# S32R372 register map
Vendor: Freescale Semiconductor, Inc.; Series: Qorivva; File version: 1.6
Registers are 32-bit, read-write, reset 0x0 unless marked. A register's access mark holds for its fields unless they carry their own. Offsets are from the block's base; [hi:lo] are bit positions; 'fields as' and 'values as' point back to an identical list.

## RGM — Unless otherwise noted, all registers may be accessed as 32-bit words, 16-bit half-words, or 8-bit bytes.
Base 0xFFFA8000; register names take the prefix RGM_
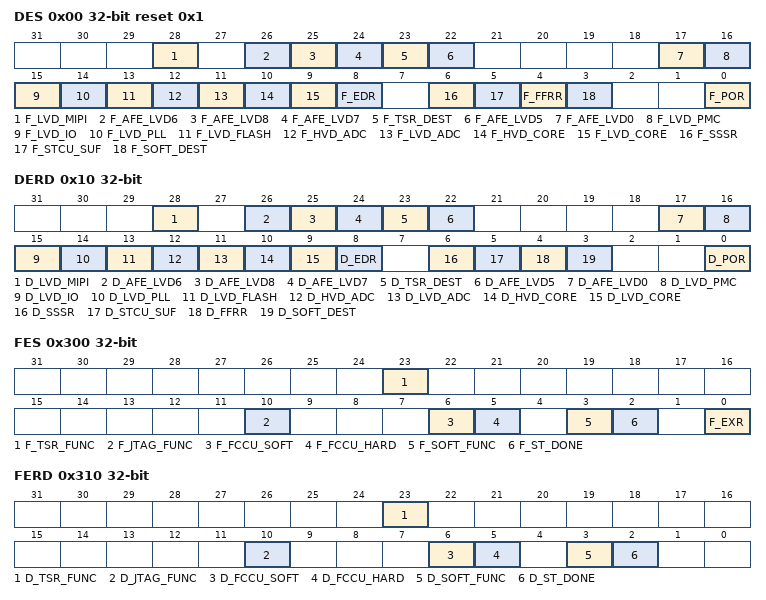
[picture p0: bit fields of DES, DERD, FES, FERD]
0x00 DES reset 0x1 — 'Destructive' Event Status Register
  [28] F_LVD_MIPI — LVD on MIPI voltage
    0=No MIPI LVD voltage 'destructive' reset event has occurred since the last clear; 1=A MIPI LVD voltage 'destructive' reset event has occurred
  [26] F_AFE_LVD6 — AFE LVD 'destructive' reset event has occurred due toAFE SDPLL analog circuitry
    0=No AFE LVD 'destructive' reset event has occurred since the last clear; 1=An AFE LVD 'destructive' reset event has occurred
  [25] F_AFE_LVD8 — AFE LVD 'destructive' reset event has occurred due to level shifter logic
    values as F_AFE_LVD6
  [24] F_AFE_LVD7 — AFE LVD 'destructive' reset event has occurred due to AFE SDPLL digital circuitry
    values as F_AFE_LVD6
  [23] F_TSR_DEST — Flag for temperature sensor 'destructive' reset
    0=No temperature sensor 'destructive' reset event has occurred since the last clear; 1=A temperature sensor 'destructive' reset event has occurred
  [22] F_AFE_LVD5 — AFE LVD 'destructive' reset event has occurred due to AFE OSC circuitry
    values as F_AFE_LVD6
  [17] F_AFE_LVD0 — AFE LVD 'destructive' reset event has occurred due to VDD_HV_RAW.
    values as F_AFE_LVD6
  [16] F_LVD_PMC — LVD on PMC voltage A destructive reset on the PMC voltage supply LVD (LVD_PMC) will also set the external reset status in RGM_FES[F_EXR]
    0=No PMC LVD voltage 'destructive' reset event has occurred since the last clear; 1=A PMC LVD voltage 'destructive' reset event has occurred
  [15] F_LVD_IO — LVD on I/O voltage
    0=No I/O LVD voltage 'destructive' reset event has occurred since the last clear; 1=An I/O LVD voltage 'destructive' reset event has occurred
  [14] F_LVD_PLL — LVD on PLL voltage
    0=No PLL LVD voltage 'destructive' reset event has occurred since the last clear; 1=A PLL LVD voltage 'destructive' reset event has occurred
  [13] F_LVD_FLASH — LVD on Flash voltage
    0=No Flash LVD voltage 'destructive' reset event has occurred since the last clear; 1=A Flash LVD voltage 'destructive' event has occurred
  [12] F_HVD_ADC — HVD on ADC voltage
    0=No ADC HVD voltage 'destructive' reset event has occurred since the last clear; 1=An ADC HVD voltage 'destructive' reset event has occurred
  [11] F_LVD_ADC — LVD on ADC voltage
    0=No ADC LVD voltage 'destructive' reset event has occurred since the last clear; 1=An ADC LVD voltage 'destructive' reset event has occurred
  [10] F_HVD_CORE — HVD on core voltage
    0=No core HVD voltage 'destructive' reset event has occurred since the last clear; 1=A core HVD voltage 'destructive' reset event has occurred
  [9] F_LVD_CORE — LVD on core voltage
    0=No core LVD voltage 'destructive' reset event has occurred since the last clear; 1=A core LVD voltage 'destructive' reset event has occurred
  [8] F_EDR — Flag for 'functional' reset escalation
    0=No 'functional' reset escalation event has occurred since the last clear; 1=A 'functional' reset escalation event has occurred
  [6] F_SSSR — Flag for SSCM Secure reset
    0=No SSCM Secure reset event has occurred since either the last clear or the last power-on reset assertion; 1=A SSCM Secure reset event has occurred
  [5] F_STCU_SUF — 'Destructive' reset event based on STCU offline selftest and STCU Critical Fault (SUF) The F_STCU_SUF destructive reset will not occur if the JCOMP is 1
    0=No SUF 'destructive' reset event has occurred since last clear; 1=A SUF 'destructive' reset event has occurred
  [4] F_FFRR — Flag for FCCU failure to react reset
    0=No FCCU failure to react reset event has occurred since the last clear; 1=A FCCU failure to react reset event has occurred
  [3] F_SOFT_DEST — Flag for software 'destructive' reset
    0=No software 'destructive' reset event has occurred since the last clear; 1=A software 'destructive' reset event has occurred
  [0] F_POR — Flag for Power-on reset
    0=No power-on event has occurred since the last clear; 1=A power-on event has occurred
0x10 DERD — 'Destructive' Event Reset Disable Register
  [28] D_LVD_MIPI ro — Disable LVD on MIPI voltage 'destructive' reset
    0=An LVD on MIPI voltage 'destructive' reset event triggers a reset sequence
  [26] D_AFE_LVD6 ro — Disable AFE LVD 'destructive' reset
    0=An AFE LVD 'destructive' reset event triggers a reset sequence
  [25] D_AFE_LVD8 ro — Disable AFE LVD 'destructive' reset
    0=An AFE LVD'destructive'reset event triggers a reset sequence
  [24] D_AFE_LVD7 ro — Disable AFE LVD 'destructive' reset
    values as D_AFE_LVD6
  [23] D_TSR_DEST — Disable temperature sensor 'destructive' reset
    0=A temperature sensor 'destructive' reset event triggers a reset sequence; 1=A temperature sensor 'destructive' reset event generates either a SAFE mode or an interrupt request depending on the value of RGM_DEAR[AR_TSR_DEST]
  [22] D_AFE_LVD5 ro — Disable AFE LVD 'destructive' reset
    values as D_AFE_LVD6
  [17] D_AFE_LVD0 ro — Disable AFE LVD 'destructive' reset
    values as D_AFE_LVD6
  [16] D_LVD_PMC ro — Disable LVD on PMC voltage 'destructive' reset
    0=An LVD on PMC voltage 'destructive' reset event triggers a reset sequence
  [15] D_LVD_IO ro — Disable LVD on I/O voltage 'destructive' reset
    0=An LVD on I/O voltage 'destructive' reset event triggers a reset sequence
  [14] D_LVD_PLL ro — Disable LVD on PLL voltage 'destructive' reset
    0=An LVD on PLL voltage 'destructive' reset event triggers a reset sequence
  [13] D_LVD_FLASH ro — Disable LVD on Flash voltage 'destructive' reset
    0=An LVD on Flash voltage 'destructive' reset event triggers a reset sequence
  [12] D_HVD_ADC ro — Disable HVD on ADC voltage 'destructive' reset
    0=An HVD on ADC voltage 'destructive' reset event triggers a reset sequence
  [11] D_LVD_ADC ro — Disable LVD on ADC voltage 'destructive' reset
    0=An LVD on ADC voltage 'destructive' reset event triggers a reset sequence
  [10] D_HVD_CORE ro — Disable HVD on core voltage 'destructive' reset
    0=An HVD on core voltage 'destructive' reset event triggers a reset sequence
  [9] D_LVD_CORE ro — Disable LVD on core voltage 'destructive' reset
    0=An LVD on core voltage 'destructive' reset event triggers a reset sequence
  [8] D_EDR ro — Disable 'functional' reset escalation
    0=A 'functional' reset escalation event triggers a reset sequence
  [6] D_SSSR ro — Disable LVD on SSCM voltage 'destructive' reset
    0=An LVD on SSCM voltage 'destructive' reset event triggers a reset sequence
  [5] D_STCU_SUF ro — Disable STCU offline selftest and STCU CF (SUF) 'destructive' reset
    0=An STCU offline selftest and STCU CF (SUF) 'destructive' reset event triggers a reset sequence
  [4] D_FFRR ro — Disable FCCU failure to react reset
    0=A FCCU failure to react reset event triggers a reset sequence
  [3] D_SOFT_DEST ro — Disable software 'destructive' reset
    0=A software 'destructive' reset triggers a reset sequence
  [0] D_POR ro — Disable Power-on reset
    0=A power-on event triggers a reset sequence
0x20 DEAR — 'Destructive' Event Alternate Request Register
  [23] AR_TSR_DEST — Alternate Request for temperature sensor 'destructive' reset
    0=Generate a SAFE mode request on a temperature sensor 'destructive' reset event if the reset is disabled; 1=Generate an interrupt request on a temperature sensor 'destructive' reset event if the reset is disabled
0x300 FES — 'Functional' Event Status Register
  [23] F_TSR_FUNC — Flag for temperature sensor 'functional' reset
    0=No temperature sensor 'functional' reset event has occurred since either the last clear or the last power-on reset assertion; 1=A temperature sensor 'functional' reset event has occurred
  [10] F_JTAG_FUNC — Flag for JTAG 'functional' reset
    0=No JTAG 'functional' reset event has occurred since either the last clear or the last power-on reset assertion; 1=A JTAG 'functional' reset event has occurred
  [6] F_FCCU_SOFT — Flag for FCCU soft reaction
    0=No FCCU soft reaction event has occurred since either the last clear or the last power-on reset assertion; 1=A FCCU soft reaction event has occurred
  [5] F_FCCU_HARD — Flag for FCCU hard reaction reset
    0=No FCCU hard reaction reset event has occurred since either the last clear or the last power-on reset assertion; 1=A FCCU hard reaction reset event has occurred
  [3] F_SOFT_FUNC — Flag for software 'functional' reset
    0=No software 'functional' reset event has occurred since either the last clear or the last power-on reset assertion; 1=A software 'functional' reset event has occurred
  [2] F_ST_DONE — Flag for self test completed
    0=No self test completed event has occurred since either the last clear or the last power-on reset assertion; 1=A self test completed event has occurred
  [0] F_EXR — Flag for extenal reset
    0=No external reset has occurred since either the last clear or last power-on reset assertion; 1=An external reset event has occurred
0x310 FERD — 'Functional' Event Reset Disable Register
  [23] D_TSR_FUNC — Disable temperature sensor 'functional' reset
    0=A temperature sensor 'functional' reset event triggers a reset sequence; 1=A temperature sensor 'functional' reset event generates either a SAFE mode or an interrupt request depending on the value of RGM_FEAR[AR_JTAG_FUNC]
  [10] D_JTAG_FUNC — Disable JTAG 'functional' reset
    0=A JTAG 'functional' reset event triggers a reset sequence; 1=A JTAG 'functional' reset event generates either a SAFE mode or an interrupt request depending on the value of RGM_FEAR[AR_JTAG_FUNC]
  [6] D_FCCU_SOFT ro — Disable FCCU soft reaction
    0=A FCCU soft reaction event triggers a reset sequence
  [5] D_FCCU_HARD ro — Disable FCCU hard reaction reset
    0=A FCCU hard reaction reset event triggers a reset sequence
  [3] D_SOFT_FUNC ro — Disable software 'functional' reset
    0=A software 'functional' reset event triggers a reset sequence
  [2] D_ST_DONE ro — Disable self test completed
    0=A self test completed event triggers a reset sequence
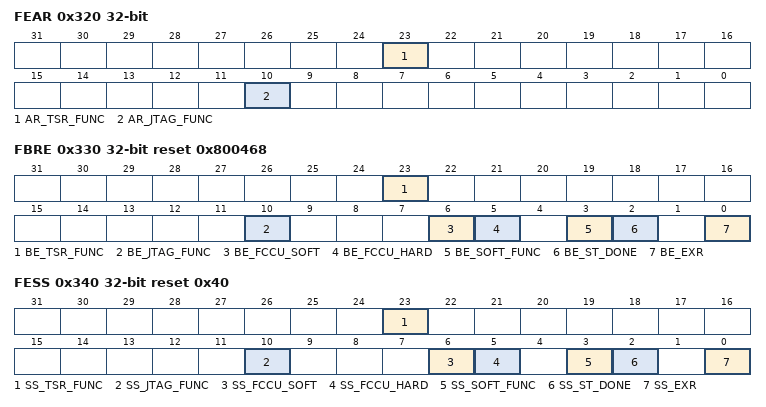
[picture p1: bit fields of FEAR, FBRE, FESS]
0x320 FEAR — 'Functional' Event Alternate Request Register
  [23] AR_TSR_FUNC — Alternate Request for temperature sensor 'functional' reset
    0=Generate a SAFE mode request on a temperature sensor 'functional' reset event if the reset is disabled; 1=Generate an interrupt request on a temperature sensor 'functional' reset event if the reset is disabled
  [10] AR_JTAG_FUNC — Alternate Request for JTAG 'functional' reset
    0=Generate a SAFE mode request on a JTAG 'functional' reset event if the reset is disabled; 1=Generate an interrupt request on a JTAG 'functional' reset event if the reset is disabled
0x330 FBRE reset 0x800468 — 'Functional' Bidirectional Reset Enable Register
  [23] BE_TSR_FUNC — Bidirectional Reset Enable for temperature sensor 'functional' reset
    0=RESET_B is asserted on a temperature sensor 'functional' reset event if the reset is enabled; 1=RESET_B is not asserted on a temperature sensor 'functional' reset event
  [10] BE_JTAG_FUNC — Bidirectional Reset Enable for JTAG 'functional' reset
    0=RESET_B is asserted on a JTAG 'functional' reset event if the reset is enabled; 1=RESET_B is not asserted on a JTAG 'functional' reset event
  [6] BE_FCCU_SOFT — Bidirectional Reset Enable for FCCU soft reaction
    0=RESET_B is asserted on a FCCU soft reaction event; 1=RESET_B is not asserted on a FCCU soft reaction event
  [5] BE_FCCU_HARD — Bidirectional Reset Enable for a FCCU hard reaction
    0=RESET_B is asserted on a FCCU hard reaction reset event; 1=RESET_B is not asserted on a FCCU hard reaction reset event
  [3] BE_SOFT_FUNC — Bidirectional Reset Enable for software 'functional' reset
    0=RESET_B is asserted on a software 'functional' reset event if the reset is enabled; 1=RESET_B is not asserted on a software 'functional' reset event
  [2] BE_ST_DONE ro — Bidirectional Reset Enable for self test completed
    0=RESET_B is asserted on a self test completed event
  [0] BE_EXR ro — Bidirectional Reset Enable for external reset
    0=RESET_B is asserted on an external reset event if the reset is enabled
0x340 FESS reset 0x40 — 'Functional' Event Short Sequence Register
  [23] SS_TSR_FUNC — Short Sequence for temperature sensor 'functional' reset
    0=The reset sequence triggered by a temperature sensor 'functional' reset event will start from PHASE1; 1=The reset sequence triggered by a temperature sensor 'functional' reset event will start from PHASE3, skipping PHASE1 and PHASE2
  [10] SS_JTAG_FUNC — Short Sequence for JTAG 'functional' reset
    0=The reset sequence triggered by a JTAG 'functional' reset event will start from PHASE1; 1=The reset sequence triggered by a JTAG 'functional' reset event will start from PHASE3, skipping PHASE1 and PHASE2
  [6] SS_FCCU_SOFT ro — Short Sequence for FCCU soft reaction
    0=The reset sequence triggered by an FCCU Soft reaction event will start from PHASE1
  [5] SS_FCCU_HARD ro — Short Sequence for a FCCU hard reaction
    0=The reset sequence triggered by an FCCU Hard reaction event will start from PHASE1
  [3] SS_SOFT_FUNC — Short Sequence for software 'functional' reset
    0=The reset sequence triggered by a Software functional reset event will start from PHASE1; 1=The reset sequence triggered by a Software functional reset event will start from PHASE3, skipping PHASE1 and PHASE2
  [2] SS_ST_DONE ro — Bidirectional Reset Enable for self test completed
    0=RESET_B is asserted on a self test completed event
  [0] SS_EXR — Short Sequence for external reset
    0=The reset sequence triggered by an external reset event will start from PHASE1; 1=The reset sequence triggered by an external reset event if the reset is enabled will start from PHASE3, skipping PHASE1 and PHASE2
0x604 FRET 8-bit reset 0xF — 'Functional' Event Short Sequence Register
  [3:0] FRET — 'Functional' Reset Escalation Threshold - If the value of this field is 0, the 'functional' reset escalation function is disabled
0x608 DRET 8-bit — Destructive Reset Escalation Threshold Register
  [3:0] DRET — 'Destructive' Reset Escalation Threshold - If the value of this field is 0, the 'destructive' reset escalation function is disabled
